CM_ "IMPORT ../../ford_lincoln_base_pt.dbc";

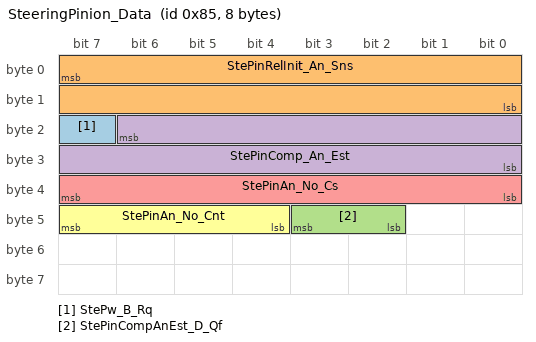
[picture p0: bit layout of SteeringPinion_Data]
BO_ 133 SteeringPinion_Data: 8 PSCM
 SG_ StePw_B_Rq : 23|1@0+ (1,0) [0|1] "SED"  GWM,ECM_Diesel,PCM
 SG_ StePinRelInit_An_Sns : 7|16@0+ (0.1,-3200) [-3200|3353.3] "degrees"  VDM,IPMA_ADAS,GWM,ECM_Diesel,PCM,PCM_HEV,ABS_ESC,TCCM
 SG_ StePinCompAnEst_D_Qf : 43|2@0+ (1,0) [0|3] "SED"  VDM,CMR_DSMC,IPMA_ADAS,TCM_DSL,ECM_Diesel,PCM,PCM_HEV,ABS_ESC,TCCM,GWM
 SG_ StePinComp_An_Est : 22|15@0+ (0.1,-1600) [-1600|1676.7] "degrees"  VDM,CMR_DSMC,IPMA_ADAS,TCM_DSL,ECM_Diesel,PCM,PCM_HEV,ABS_ESC,TCCM,GWM
 SG_ StePinAn_No_Cs : 39|8@0+ (1,0) [0|255] "Unitless"  VDM,ABS_ESC,TCCM,GWM
 SG_ StePinAn_No_Cnt : 47|4@0+ (1,0) [0|15] "unitless"  VDM,TCCM,GWM,ABS_ESC

CM_ SG_ 133 StePinRelInit_An_Sns "SASM will transmit these signals on vehicles with SASM and without PSCM.  SCCM will not Tx this signal when SASM is present.";
CM_ SG_ 133 StePinAn_No_Cs "Signal not transmitted on gas variants.";

BA_ "FrameRouting" BO_ 133 "";
BA_ "GenMsgSendType" BO_ 133 0;
BA_ "GenMsgCycleTime" BO_ 133 10;
BA_ "GenMsgDelayTime" BO_ 133 0;
BA_ "VFrameFormat" BO_ 133 14;
BA_ "UsedOnPgmDBC" SG_ 133 StePw_B_Rq 1;
BA_ "U_P702_MY2021_Rx" SG_ 133 StePw_B_Rq 1;
BA_ "U_T6_MCA_MY2020_Rx" SG_ 133 StePw_B_Rq 1;
BA_ "U_P702_MY2021_Tx" SG_ 133 StePw_B_Rq 1;
BA_ "UsedOnPgmDBC" SG_ 133 StePinRelInit_An_Sns 1;
BA_ "GenSigStartValueInteger" SG_ 133 StePinRelInit_An_Sns 65535;
BA_ "ContentDependant" SG_ 133 StePinRelInit_An_Sns 1;
BA_ "GenSigStartValue" SG_ 133 StePinRelInit_An_Sns 65535;
BA_ "U_P702_MY2021_Rx" SG_ 133 StePinRelInit_An_Sns 1;
BA_ "U_CX727_MY2021_Rx" SG_ 133 StePinRelInit_An_Sns 1;
BA_ "U_T6_MCA_MY2020_Rx" SG_ 133 StePinRelInit_An_Sns 1;
BA_ "U_CX727_MY2021_Tx" SG_ 133 StePinRelInit_An_Sns 1;
BA_ "U_P702_MY2021_Tx" SG_ 133 StePinRelInit_An_Sns 1;
BA_ "CrossOver_InfoCAN" SG_ 133 StePinCompAnEst_D_Qf 1;
BA_ "UsedOnPgmDBC" SG_ 133 StePinCompAnEst_D_Qf 1;
BA_ "GenSigStartValueInteger" SG_ 133 StePinCompAnEst_D_Qf 1;
BA_ "GenSigStartValue" SG_ 133 StePinCompAnEst_D_Qf 1;
BA_ "U_P702_MY2021_Rx" SG_ 133 StePinCompAnEst_D_Qf 1;
BA_ "U_CX727_MY2021_Rx" SG_ 133 StePinCompAnEst_D_Qf 1;
BA_ "U_T6_MCA_MY2020_Rx" SG_ 133 StePinCompAnEst_D_Qf 1;
BA_ "U_CX727_MY2021_Tx" SG_ 133 StePinCompAnEst_D_Qf 1;
BA_ "U_P702_MY2021_Tx" SG_ 133 StePinCompAnEst_D_Qf 1;
BA_ "ECGUsedRxSignal" SG_ 133 StePinCompAnEst_D_Qf 1;
BA_ "GenSigStartValueInteger" SG_ 133 StePinComp_An_Est 16000;
BA_ "U_P702_MY2021_Rx" SG_ 133 StePinComp_An_Est 1;
BA_ "U_CX727_MY2021_Rx" SG_ 133 StePinComp_An_Est 1;
BA_ "U_T6_MCA_MY2020_Rx" SG_ 133 StePinComp_An_Est 1;
BA_ "U_CX727_MY2021_Tx" SG_ 133 StePinComp_An_Est 1;
BA_ "U_P702_MY2021_Tx" SG_ 133 StePinComp_An_Est 1;
BA_ "ECGUsedRxSignal" SG_ 133 StePinComp_An_Est 1;
BA_ "UsedOnPgmDBC" SG_ 133 StePinAn_No_Cs 1;
BA_ "ContentDependant" SG_ 133 StePinAn_No_Cs 1;
BA_ "MetaData" SG_ 133 StePinAn_No_Cs 1;
BA_ "U_P702_MY2021_Rx" SG_ 133 StePinAn_No_Cs 1;
BA_ "U_CX727_MY2021_Rx" SG_ 133 StePinAn_No_Cs 1;
BA_ "U_CX727_MY2021_Tx" SG_ 133 StePinAn_No_Cs 1;
BA_ "U_P702_MY2021_Tx" SG_ 133 StePinAn_No_Cs 1;
BA_ "CrossOver_InfoCAN" SG_ 133 StePinAn_No_Cnt 1;
BA_ "MetaData" SG_ 133 StePinAn_No_Cnt 1;
BA_ "U_P702_MY2021_Rx" SG_ 133 StePinAn_No_Cnt 1;
BA_ "U_CX727_MY2021_Rx" SG_ 133 StePinAn_No_Cnt 1;
BA_ "U_CX727_MY2021_Tx" SG_ 133 StePinAn_No_Cnt 1;
BA_ "U_P702_MY2021_Tx" SG_ 133 StePinAn_No_Cnt 1;

VAL_ 133 StePw_B_Rq 1 "Yes" 0 "No";
VAL_ 133 StePinRelInit_An_Sns 65535 "Faulty" 65534 "NoDataExists";
VAL_ 133 StePinCompAnEst_D_Qf 3 "OK" 2 "Degraded" 1 "No_Data_Exists" 0 "Faulty";
